# ATmega32U4 register map
Vendor: Atmel; File version: 1.0
CPU: other r0p0, little endian, no MPU, no FPU, 4 interrupt priority bits
Registers are 8-bit, read-write, reset 0x0 unless marked. A register's access mark holds for its fields unless they carry their own. Offsets are from the block's base; [hi:lo] are bit positions; {n}, {i} and the like mark numbered series.

## ADC — Analog-to-Digital Converter
Base 0x00800078
0x00 ADC 16-bit (reset mask 0xFF) — ADC Data Register Bytes
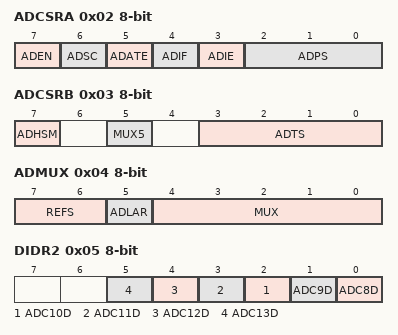
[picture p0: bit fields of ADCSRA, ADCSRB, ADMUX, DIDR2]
0x02 ADCSRA — The ADC Control and Status register (read-only for debugger)
  [7] ADEN — ADC Enable
  [6] ADSC — ADC Start Conversion
  [5] ADATE — ADC Auto Trigger Enable
  [4] ADIF — ADC Interrupt Flag
  [3] ADIE — ADC Interrupt Enable
  [2:0] ADPS — ADC Prescaler Select Bits
    1=2; 2=4; 3=8; 4=16; 5=32; 6=64; 7=128
0x03 ADCSRB — ADC Control and Status Register B
  [7] ADHSM — ADC High Speed Mode
  [5] MUX5 — Analog Channel and Gain Selection Bits
  [3:0] ADTS — ADC Auto Trigger Sources
    0=FREE_RUNNING_MODE; 1=ANALOG_COMPARATOR; 2=EXTERNAL_INTERRUPT_REQUEST_0; 3=TIMER_COUNTER0_COMPARE_MATCH_A; 4=TIMER_COUNTER0_OVERFLOW; 5=TIMER_COUNTER1_COMPARE_MATCH_B; 6=TIMER_COUNTER1_OVERFLOW; 7=TIMER_COUNTER1_CAPTURE_EVENT; 8=TIMER_COUNTER4_OVERFLOW; 9=TIMER_COUNTER4_COMPARE_MATCH_A; 10=TIMER_COUNTER4_COMPARE_MATCH_B; 11=TIMER_COUNTER4_COMPARE_MATCH_D
0x04 ADMUX — The ADC multiplexer Selection Register
  [7:6] REFS — Reference Selection Bits
    0=AREF_INTERNAL_VREF_TURNED_OFF; 1=AVCC_WITH_EXTERNAL_CAPACITOR_AT_AREF_PIN; 3=INTERNAL_2_56V_VOLTAGE_REFERENCE_WITH_EXTERNAL_CAPACITOR_AT_AREF_PIN
  [5] ADLAR — Left Adjust Result
  [4:0] MUX — Analog Channel and Gain Selection Bits
0x05 DIDR2 — Digital Input Disable Register 2
  [n-8] ADC{n}D (n=8..13) — ADC{n} Digital input Disable
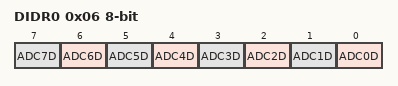
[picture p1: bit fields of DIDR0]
0x06 DIDR0 — Digital Input Disable Register 0
  [n] ADC{n}D (n=0..7) — ADC{n} Digital input Disable

## BOOT_LOAD — Bootloader
Base 0x00800057
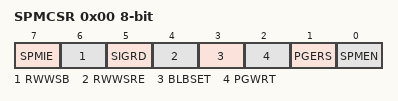
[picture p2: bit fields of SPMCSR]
0x00 SPMCSR — Store Program Memory Control Register
  [7] SPMIE — SPM Interrupt Enable
  [6] RWWSB — Read While Write Section Busy
  [5] SIGRD — Signature Row Read
  [4] RWWSRE — Read While Write section read enable
  [3] BLBSET — Boot Lock Bit Set
  [2] PGWRT — Page Write
  [1] PGERS — Page Erase
  [0] SPMEN — Store Program Memory Enable

## CPU — CPU Registers
Base 0x0080003E
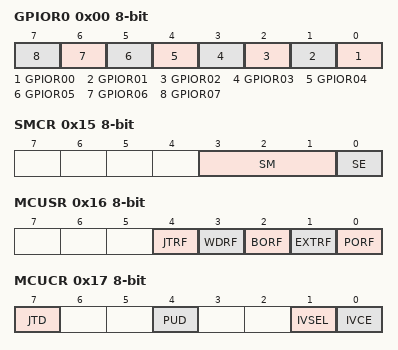
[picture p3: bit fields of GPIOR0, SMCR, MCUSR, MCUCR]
0x00 GPIOR0 — General Purpose IO Register 0
  [n] GPIOR{n:02} (n=0..7) — General Purpose IO Register 0 bit {n}
0x0C GPIOR1 — General Purpose IO Register 1
  [7:0] GPIOR — General Purpose IO Register 1 bis
0x0D GPIOR2 — General Purpose IO Register 2
  [7:0] GPIOR — General Purpose IO Register 2 bis
0x15 SMCR — Sleep Mode Control Register
  [3:1] SM — Sleep Mode Select bits
    0=IDLE; 1=ADC (ADC Noise Reduction (If Available)); 2=PDOWN (Power Down); 3=PSAVE (Power Save); 6=STDBY (Standby); 7=ESTDBY (Extended Standby)
  [0] SE — Sleep Enable
0x16 MCUSR — MCU Status Register
  [4] JTRF — JTAG Reset Flag
  [3] WDRF — Watchdog Reset Flag
  [2] BORF — Brown-out Reset Flag
  [1] EXTRF — External Reset Flag
  [0] PORF — Power-on reset flag
0x17 MCUCR — MCU Control Register
  [7] JTD — JTAG Interface Disable
  [4] PUD — Pull-up disable
  [1] IVSEL — Interrupt Vector Select
  [0] IVCE — Interrupt Vector Change Enable
0x1D RAMPZ — Extended Z-pointer Register for ELPM/SPM
  [1:0] RAMPZ — Extended Z-Pointer Value
    0=DEFAULT_VALUE_OF_Z_POINTER_MSB_S
0x1E EIND — Extended Indirect Register
0x1F SP 16-bit (reset mask 0xFF) — Stack Pointer
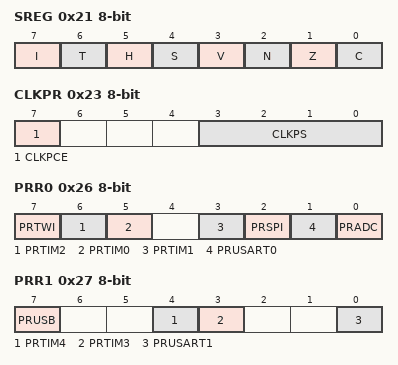
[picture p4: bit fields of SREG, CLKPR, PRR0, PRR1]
0x21 SREG — Status Register
  [7] I — Global Interrupt Enable
  [6] T — Bit Copy Storage
  [5] H — Half Carry Flag
  [4] S — Sign Bit
  [3] V — Two's Complement Overflow Flag
  [2] N — Negative Flag
  [1] Z — Zero Flag
  [0] C — Carry Flag
0x23 CLKPR
  [7] CLKPCE
  [3:0] CLKPS
    0=1; 1=2; 2=4; 3=8; 4=16; 5=32; 6=64; 7=128; 8=256
0x26 PRR0 — Power Reduction Register0
  [7] PRTWI — Power Reduction TWI
  [6] PRTIM2 — Power Reduction Timer/Counter2
  [5] PRTIM0 — Power Reduction Timer/Counter0
  [3] PRTIM1 — Power Reduction Timer/Counter1
  [2] PRSPI — Power Reduction Serial Peripheral Interface
  [1] PRUSART0 — Power Reduction USART
  [0] PRADC — Power Reduction ADC
0x27 PRR1 — Power Reduction Register1
  [7] PRUSB — Power Reduction USB
  [4] PRTIM4 — Power Reduction Timer/Counter4
  [3] PRTIM3 — Power Reduction Timer/Counter3
  [0] PRUSART1 — Power Reduction USART1
0x28 OSCCAL — Oscillator Calibration Value
  [7:0] OSCCAL — Oscillator Calibration
0x29 RCCTRL — Oscillator Control Register
  [0] RCFREQ
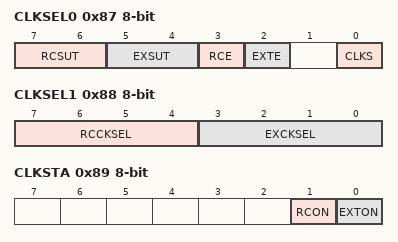
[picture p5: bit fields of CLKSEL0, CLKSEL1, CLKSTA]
0x87 CLKSEL0
  [7:6] RCSUT, [5:4] EXSUT, [3] RCE, [2] EXTE, [0] CLKS
0x88 CLKSEL1
  [7:4] RCCKSEL, [3:0] EXCKSEL
0x89 CLKSTA
  [1] RCON, [0] EXTON
